# netx90_app register map
File version: 1.0
CPU: CM4 r0p1, little endian, MPU, FPU, 4 interrupt priority bits, 78 interrupts
Registers are 32-bit, read-write, reset 0x0 unless marked. A register's access mark holds for its fields unless they carry their own. Offsets are from the block's base; [hi:lo] are bit positions; {n}, {i} and the like mark numbered series; 'fields as' and 'values as' point back to an identical list; <NAME> marks a mode.

## menc_app
Base 0xFF802300
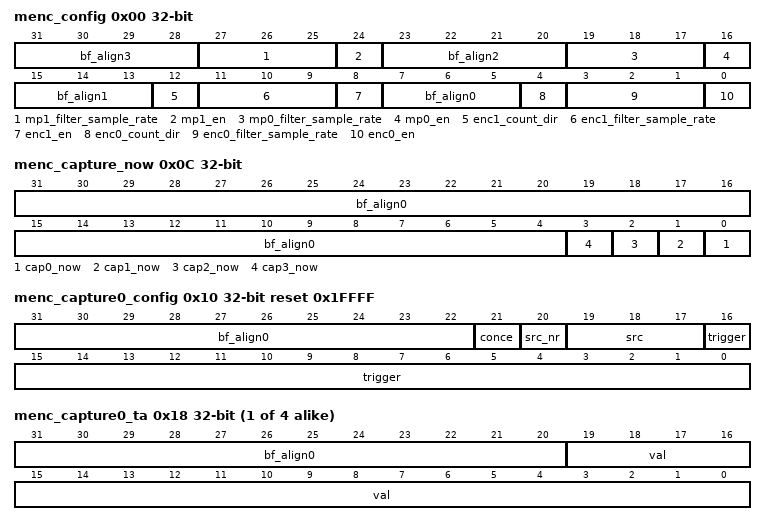
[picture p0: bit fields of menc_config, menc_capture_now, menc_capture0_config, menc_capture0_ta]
0x00 menc_config (reset mask 0xF0F1F1F) — Encoder configuration register
  [31:28] bf_align3 — bitField alignment value for aeabi compatibility
  [27:25] mp1_filter_sample_rate — Filter sample rate for mp1 signal: { | 0: none - Filter is disabled. 1: 10 ns - pulses < 10ns will be blocked, pulses > 20ns will pass. 2: 20 ns - pulses < 20ns will be blocked, pulses > 40ns will pass. 3: 50 ns - pulses < 50ns will be blocked, pulses > 100ns will pass. 4: 100 ns - pulses < 100ns will be blocked, pulses > 200ns will pass. 5: 200 ns - pulses < 200ns will be blocked, pulses > 400ns will pass. 6: 500 ns - pulses < 500ns will be blocked, pulses > 1us will pass. 7: 1 us - pulses < 1us will be blocked, pulses > 2us will pass. }
  [24] mp1_en — mp1 enable: 0: Disable interrupts based on mp1 signal.
  [23:20] bf_align2 — bitField alignment value for aeabi compatibility
  [19:17] mp0_filter_sample_rate — Filter sample rate for mp0 signal: { | 0: none - Filter is disabled. 1: 10 ns - pulses < 10ns will be blocked, pulses > 20ns will pass. 2: 20 ns - pulses < 20ns will be blocked, pulses > 40ns will pass. 3: 50 ns - pulses < 50ns will be blocked, pulses > 100ns will pass. 4: 100 ns - pulses < 100ns will be blocked, pulses > 200ns will pass. 5: 200 ns - pulses < 200ns will be blocked, pulses > 400ns will pass. 6: 500 ns - pulses < 500ns will be blocked, pulses > 1us will pass. 7: 1 us - pulses < 1us will be blocked, pulses > 2us will pass. }
  [16] mp0_en — mp0 enable: 0: Disable interrupts based on mp0 signal.
  [15:13] bf_align1 — bitField alignment value for aeabi compatibility
  [12] enc1_count_dir — Encoder1 count direction: 0: standard 1: inverted
  [11:9] enc1_filter_sample_rate — Encoder1 filter sample rate: { | 0: none - Filter is disabled. 1: 10 ns - pulses < 10ns will be blocked, pulses > 20ns will pass. 2: 20 ns - pulses < 20ns will be blocked, pulses > 40ns will pass. 3: 50 ns - pulses < 50ns will be blocked, pulses > 100ns will pass. 4: 100 ns - pulses < 100ns will be blocked, pulses > 200ns will pass. 5: 200 ns - pulses < 200ns will be blocked, pulses > 400ns will pass. 6: 500 ns - pulses < 500ns will be blocked, pulses > 1us will pass. 7: 1 us - pulses < 1us will be blocked, pulses > 2us will pass. }
  [8] enc1_en — Encoder1 enable: 0: Disable interrupts based on encoder1 signals.
  [7:5] bf_align0 — bitField alignment value for aeabi compatibility
  [4] enc0_count_dir — Encoder0 count direction: 0: standard 1: inverted
  [3:1] enc0_filter_sample_rate — Encoder0 filter sample rate: { | 0: none - Filter is disabled. 1: 10 ns - pulses < 10ns will be blocked, pulses > 20ns will pass. 2: 20 ns - pulses < 20ns will be blocked, pulses > 40ns will pass. 3: 50 ns - pulses < 50ns will be blocked, pulses > 100ns will pass. 4: 100 ns - pulses < 100ns will be blocked, pulses > 200ns will pass. 5: 200 ns - pulses < 200ns will be blocked, pulses > 400ns will pass. 6: 500 ns - pulses < 500ns will be blocked, pulses > 1us will pass. 7: 1 us - pulses < 1us will be blocked, pulses > 2us will pass. }
  [0] enc0_en — Encoder0 enable: 0: Disable interrupts based on encoder0 signals.
0x04 menc_enc0_position — Position of encoder 0
  [31:0] val — Actual position of encoder 0. This register is writable but can also be changed by hardware.
0x08 menc_enc1_position — Position of encoder 1
  [31:0] val — Actual position of encoder 1. This register is writable but can also be changed by hardware.
0x0C menc_capture_now (reset mask 0xF) — Capture now register: This register allows activating the capture event by software for all 4 capture units.
  [31:4] bf_align0 — bitField alignment value for aeabi compatibility
  [n] cap{n}_now (n=0..3) — Capture menc_capture{n} now (by SW). Capture by writing 1 to this register, reset automatically.
0x10 menc_capture0_config reset 0x1FFFF (reset mask 0x3FFFFF) — Capture unit 0 configuration register
  [31:22] bf_align0 — bitField alignment value for aeabi compatibility
  [21] conce — Capture once: 0: continuous capture: each event overwrites old capture register 1: capture once: capture only, if menc_status.cap0 = 0
  [20] src_nr — Capture source channel: 0: encoder/channel 0 1: encoder/channel 1
  [19:17] src — Capture source (what to capture): 0: system time ns (independent of src_nr) 1: position channel 0/1 2: Ta of channel 0/1 3: Te of channel 0/1 4: Ta+Te of channel 0/1 5: period in clock cycles (independent of src_nr)
  [16:0] trigger — Capture start signal: 0x0...0x0FFFF: start at (ECNT == trigger) 0x10000: positive edge of enc0_n 0x10001: negative edge of enc0_n 0x10002: positive edge of enc1_n 0x10003: positive edge of enc1_n 0x10004: any edge of enc0_a or enc0_b 0x10005: any edge of enc1_a or enc0_b 0x10006: positive edge of mp0 0x10007: negative edge of mp0 0x10008: positive edge of mp1 0x10009: negative edge of mp1 0x1000a: GPIO_APP_COUNTER0 = 0 0x1000b: GPIO_APP_COUNTER1 = 0 0x1000c: GPIO_APP_COUNTER2 = 0 0x1000d: positive edge of xc_trigger[0] 0x1000e: positive edge of xc_trigger[1] 0x1000f: negative edge of xc_trigger[0] 0x10010: negative edge of xc_trigger[1] 0x10011: positive edge of xc_sample[0] 0x10012: positive edge of xc_sample[1] 0x10013: negative edge of xc_sample[0] 0x10014: negative edge of xc_sample[1] 0x1FFFF: off (no automatic capture, only capture_now)
{0x14+0x10*i} menc_capture{i}_val ro (i=0..3) — Capture unit {i} captured value
  [31:0] val — Captured value
{0x18+0x10*i} menc_capture{i}_ta ro (reset mask 0xFFFFF) (i=0..3) — Capture unit {i} Ta: This register is only used for debug purposes.
  [31:20] bf_align0 — bitField alignment value for aeabi compatibility
  [19:0] val — Actual Ta: Time before first encoder pulse in period.
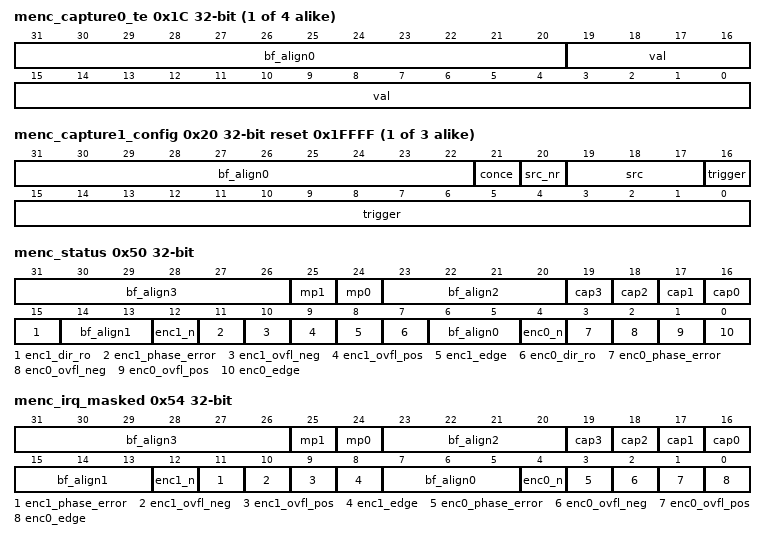
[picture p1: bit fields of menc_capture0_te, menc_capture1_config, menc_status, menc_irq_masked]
{0x1C+0x10*i} menc_capture{i}_te ro (reset mask 0xFFFFF) (i=0..3) — Capture unit {i} Te This register is only used for debug purposes.
  [31:20] bf_align0 — bitField alignment value for aeabi compatibility
  [19:0] val — Actual Te: Time after last encoder pulse in period.
{0x10+0x10*i} menc_capture{i}_config reset 0x1FFFF (reset mask 0x3FFFFF) (i=1..3) — Capture unit {i} configuration register
  [31:22] bf_align0 — bitField alignment value for aeabi compatibility
  [21] conce — Capture once: 0: continuous capture: each event overwrites old capture register 1: capture once: capture only, if menc_status.cap0 = 0
  [20] src_nr — Capture source channel: 0: encoder/channel 0 1: encoder/channel 1
  [19:17] src — Capture source (what to capture): s. capture0_config-src
  [16:0] trigger — Capture start signal: s. capture0_config-trigger
0x50 menc_status (reset mask 0x30F9F9F) — Position and capture status: This register includes all raw IRQs and encoder direction. To reset an IRQ, write 1 to appropriate bit (except enc?_dir_ro).
  [31:26] bf_align3 — bitField alignment value for aeabi compatibility
  [25] mp1 — Rising edge at Measurement Point 1
  [24] mp0 — Rising edge at Measurement Point 0
  [23:20] bf_align2 — bitField alignment value for aeabi compatibility
  [n+16] cap{n} (n=0..3) — Captured register {n}
  [15] enc1_dir_ro — Encoder1 direction (read only)
  [14:13] bf_align1 — bitField alignment value for aeabi compatibility
  [12] enc1_n — Rising edge at input enc1_n.
  [11] enc1_phase_error — Phase error at encoder 1: Encoder inputs changed 2 phases in 1 cycle, which leads to unknown position.
  [10] enc1_ovfl_neg — Encoder1 overflow negative
  [9] enc1_ovfl_pos — Encoder1 overflow positive
  [8] enc1_edge — Edge at Encoder 1 occurred (rising or falling of enc1_a or enc1_b)
  [7] enc0_dir_ro — Encoder0 direction (read only)
  [6:5] bf_align0 — bitField alignment value for aeabi compatibility
  [4] enc0_n — Rising edge at input enc0_n.
  [3] enc0_phase_error — Phase error at encoder 0: Encoder inputs changed 2 phases in 1 cycle, which leads to unknown position.
  [2] enc0_ovfl_neg — Encoder0 overflow negative
  [1] enc0_ovfl_pos — Encoder0 overflow positive
  [0] enc0_edge — Edge at Encoder 0 occurred (rising or falling of enc0_a or enc0_b)
0x54 menc_irq_masked ro (reset mask 0x30F1F1F) — Masked IRQ register: Shows status of masked IRQs (as connected to ARM/xPIC).
  [31:26] bf_align3 — bitField alignment value for aeabi compatibility
  [25] mp1 — Rising edge at Measurement Point 1
  [24] mp0 — Rising edge at Measurement Point 0
  [23:20] bf_align2 — bitField alignment value for aeabi compatibility
  [n+16] cap{n} (n=0..3) — Captured register {n}
  [15:13] bf_align1 — bitField alignment value for aeabi compatibility
  [12] enc1_n — Rising edge at input enc1_n.
  [11] enc1_phase_error — Phase error at encoder 1: Encoder inputs changed 2 phases in 1 cycle, which leads to unknown position.
  [10] enc1_ovfl_neg — Encoder1 overflow negative
  [9] enc1_ovfl_pos — Encoder1 overflow positive
  [8] enc1_edge — Edge at Encoder 1 occurred (rising or falling of enc1_a or enc1_b)
  [7:5] bf_align0 — bitField alignment value for aeabi compatibility
  [4] enc0_n — Rising edge at input enc0_n.
  [3] enc0_phase_error — Phase error at encoder 0: Encoder inputs changed 2 phases in 1 cycle, which leads to unknown position.
  [2] enc0_ovfl_neg — Encoder0 overflow negative
  [1] enc0_ovfl_pos — Encoder0 overflow positive
  [0] enc0_edge — Edge at Encoder 0 occurred (rising or falling of enc0_a or enc0_b)
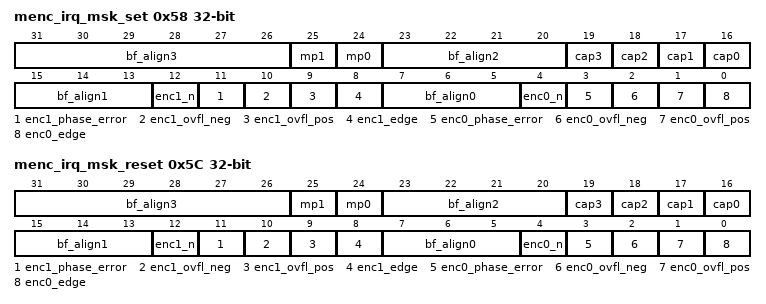
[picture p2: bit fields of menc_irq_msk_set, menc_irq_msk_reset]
0x58 menc_irq_msk_set (reset mask 0x30F1F1F) — IRQ mask enable: The IRQ mask enables interrupt requests for corresponding interrupt sources. As its bits might be changed by different software tasks, the IRQ mask register is not writable directly, but by set and reset masks: Write access with '1' sets interrupt mask bit. Write access with '0' does not influence this bit. Read access shows actual interrupt mask. Attention: Before activating interrupt mask, delete old pending interrupts by writing the same value to adr_menc_status
  fields as menc_irq_masked
0x5C menc_irq_msk_reset (reset mask 0x30F1F1F) — IRQ mask disable: This is the corresponding reset mask to disable interrupt requests for corresponding interrupt sources: Write access with '1' resets interrupt mask bit. Write access with '0' does not influence this bit. Read access shows actual interrupt mask.
  fields as menc_irq_masked
